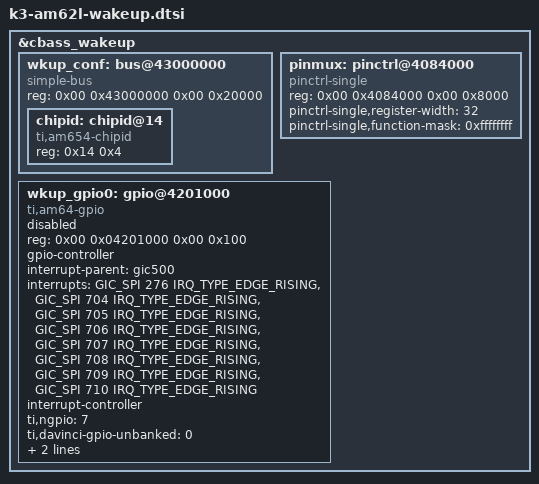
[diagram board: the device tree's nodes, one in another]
// SPDX-License-Identifier: GPL-2.0-only or MIT
/*
 * Device Tree file for the AM62L wakeup domain peripherals
 * Copyright (C) 2024 Texas Instruments Incorporated - https://www.ti.com/
 */

&cbass_wakeup {
	wkup_conf: bus@43000000 {
		bootph-all;
		compatible = "simple-bus";
		reg = <0x00 0x43000000 0x00 0x20000>;
		#address-cells = <1>;
		#size-cells = <1>;
		ranges = <0x0 0x00 0x43000000 0x20000>;

		chipid: chipid@14 {
			bootph-all;
			compatible = "ti,am654-chipid";
			reg = <0x14 0x4>;
		};
	};

	pinmux: pinctrl@4084000 {
		bootph-all;
		compatible = "pinctrl-single";
		reg = <0x00 0x4084000 0x00 0x8000>;
		#pinctrl-cells = <1>;
		pinctrl-single,register-width = <32>;
		pinctrl-single,function-mask = <0xffffffff>;
	};

	wkup_gpio0: gpio@4201000 {
		compatible = "ti,am64-gpio", "ti,keystone-gpio";
		reg = <0x00 0x04201000 0x00 0x100>;
		gpio-controller;
		#gpio-cells = <2>;
		interrupt-parent = <&gic500>;
		interrupts = <GIC_SPI 276 IRQ_TYPE_EDGE_RISING>, <GIC_SPI 704 IRQ_TYPE_EDGE_RISING>,
			     <GIC_SPI 705 IRQ_TYPE_EDGE_RISING>, <GIC_SPI 706 IRQ_TYPE_EDGE_RISING>,
			     <GIC_SPI 707 IRQ_TYPE_EDGE_RISING>, <GIC_SPI 708 IRQ_TYPE_EDGE_RISING>,
			     <GIC_SPI 709 IRQ_TYPE_EDGE_RISING>, <GIC_SPI 710 IRQ_TYPE_EDGE_RISING>;
		interrupt-controller;
		#interrupt-cells = <2>;
		ti,ngpio = <7>;
		ti,davinci-gpio-unbanked = <0>;
		power-domains = <&scmi_pds 36>;
		clocks = <&scmi_clk 142>;
		clock-names = "gpio";
		status = "disabled";
	};
};

